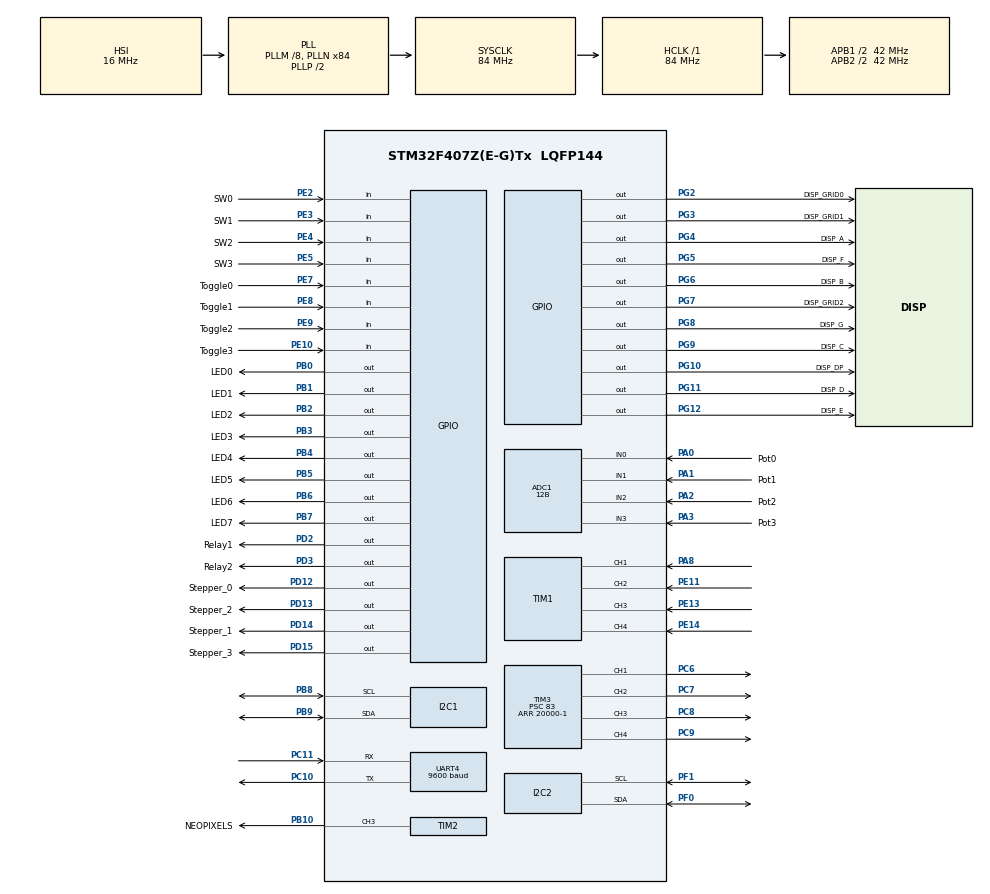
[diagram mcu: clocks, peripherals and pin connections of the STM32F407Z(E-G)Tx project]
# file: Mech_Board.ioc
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ADC1.Channel-0\#ChannelRegularConversion=ADC_CHANNEL_0
ADC1.Channel-1\#ChannelRegularConversion=ADC_CHANNEL_1
ADC1.Channel-2\#ChannelRegularConversion=ADC_CHANNEL_2
ADC1.Channel-3\#ChannelRegularConversion=ADC_CHANNEL_3
ADC1.ClockPrescaler=ADC_CLOCK_SYNC_PCLK_DIV8
ADC1.ContinuousConvMode=ENABLE
ADC1.DMAContinuousRequests=ENABLE
ADC1.NbrOfConversion=4
ADC1.NbrOfConversionFlag=1
ADC1.Rank-0\#ChannelRegularConversion=1
ADC1.Rank-1\#ChannelRegularConversion=2
ADC1.Rank-2\#ChannelRegularConversion=3
ADC1.Rank-3\#ChannelRegularConversion=4
ADC1.Resolution=ADC_RESOLUTION_12B
ADC1.SamplingTime-0\#ChannelRegularConversion=ADC_SAMPLETIME_3CYCLES
ADC1.SamplingTime-1\#ChannelRegularConversion=ADC_SAMPLETIME_3CYCLES
ADC1.SamplingTime-2\#ChannelRegularConversion=ADC_SAMPLETIME_3CYCLES
ADC1.SamplingTime-3\#ChannelRegularConversion=ADC_SAMPLETIME_3CYCLES
ADC1.ScanConvMode=ENABLE
ADC1.master=1
Dma.ADC1.1.Direction=DMA_PERIPH_TO_MEMORY
Dma.ADC1.1.FIFOMode=DMA_FIFOMODE_DISABLE
Dma.ADC1.1.Instance=DMA2_Stream0
Dma.ADC1.1.MemDataAlignment=DMA_MDATAALIGN_HALFWORD
Dma.ADC1.1.MemInc=DMA_MINC_ENABLE
Dma.ADC1.1.Mode=DMA_CIRCULAR
Dma.ADC1.1.PeriphDataAlignment=DMA_PDATAALIGN_HALFWORD
Dma.ADC1.1.PeriphInc=DMA_PINC_DISABLE
Dma.ADC1.1.Priority=DMA_PRIORITY_LOW
Dma.Request0=TIM2_UP/CH3
Dma.Request1=ADC1
Dma.Request2=TIM3_CH3
Dma.Request3=TIM3_CH4/UP
Dma.TIM2_UP/CH3.0.Direction=DMA_MEMORY_TO_PERIPH
Dma.TIM2_UP/CH3.0.FIFOMode=DMA_FIFOMODE_DISABLE
Dma.TIM2_UP/CH3.0.Instance=DMA1_Stream1
Dma.TIM2_UP/CH3.0.MemDataAlignment=DMA_MDATAALIGN_WORD
Dma.TIM2_UP/CH3.0.MemInc=DMA_MINC_ENABLE
Dma.TIM2_UP/CH3.0.Mode=DMA_NORMAL
Dma.TIM2_UP/CH3.0.PeriphDataAlignment=DMA_PDATAALIGN_WORD
Dma.TIM2_UP/CH3.0.PeriphInc=DMA_PINC_DISABLE
Dma.TIM2_UP/CH3.0.Priority=DMA_PRIORITY_LOW
Dma.TIM3_CH3.2.Direction=DMA_MEMORY_TO_PERIPH
Dma.TIM3_CH3.2.FIFOMode=DMA_FIFOMODE_DISABLE
Dma.TIM3_CH3.2.Instance=DMA1_Stream7
Dma.TIM3_CH3.2.MemDataAlignment=DMA_MDATAALIGN_HALFWORD
Dma.TIM3_CH3.2.MemInc=DMA_MINC_ENABLE
Dma.TIM3_CH3.2.Mode=DMA_NORMAL
Dma.TIM3_CH3.2.PeriphDataAlignment=DMA_PDATAALIGN_HALFWORD
Dma.TIM3_CH3.2.PeriphInc=DMA_PINC_DISABLE
Dma.TIM3_CH3.2.Priority=DMA_PRIORITY_LOW
Dma.TIM3_CH4/UP.3.Direction=DMA_MEMORY_TO_PERIPH
Dma.TIM3_CH4/UP.3.FIFOMode=DMA_FIFOMODE_DISABLE
Dma.TIM3_CH4/UP.3.Instance=DMA1_Stream2
Dma.TIM3_CH4/UP.3.MemDataAlignment=DMA_MDATAALIGN_HALFWORD
Dma.TIM3_CH4/UP.3.MemInc=DMA_MINC_ENABLE
Dma.TIM3_CH4/UP.3.Mode=DMA_NORMAL
Dma.TIM3_CH4/UP.3.PeriphDataAlignment=DMA_PDATAALIGN_HALFWORD
Dma.TIM3_CH4/UP.3.PeriphInc=DMA_PINC_DISABLE
Dma.TIM3_CH4/UP.3.Priority=DMA_PRIORITY_LOW
Mcu.Family=STM32F4
Mcu.Name=STM32F407Z(E-G)Tx
Mcu.Package=LQFP144
NVIC.DMA1_Stream1_IRQn=true\:0\:0\:true\:false\:true\:false\:true\:true
NVIC.DMA1_Stream2_IRQn=true\:0\:0\:false\:false\:true\:false\:true\:true
NVIC.DMA1_Stream7_IRQn=true\:0\:0\:false\:false\:true\:false\:true\:true
NVIC.DMA2_Stream0_IRQn=true\:0\:0\:false\:false\:true\:false\:true\:true
NVIC.PriorityGroup=NVIC_PRIORITYGROUP_4
NVIC.TIM1_CC_IRQn=true\:0\:0\:false\:false\:true\:true\:true\:true
NVIC.TIM2_IRQn=true\:0\:0\:false\:false\:true\:true\:true\:true
NVIC.TIM4_IRQn=true\:0\:0\:true\:false\:true\:true\:true\:true
NVIC.TIM5_IRQn=true\:0\:0\:false\:false\:true\:true\:true\:true
NVIC.TIM6_DAC_IRQn=true\:0\:0\:false\:false\:true\:true\:true\:true
NVIC.TIM7_IRQn=true\:0\:0\:true\:false\:true\:true\:true\:true
NVIC.UART4_IRQn=true\:0\:0\:false\:false\:true\:true\:true\:true
PA0-WKUP.GPIO_Label=Pot0
PA0-WKUP.Signal=ADCx_IN0
PA1.GPIO_Label=Pot1
PA1.Signal=ADCx_IN1
PA2.GPIO_Label=Pot2
PA2.Signal=ADCx_IN2
PA3.GPIO_Label=Pot3
PA3.Signal=ADCx_IN3
PA8.Signal=S_TIM1_CH1
PB0.GPIO_Label=LED0
PB0.Signal=GPIO_Output
PB1.GPIO_Label=LED1
PB1.Signal=GPIO_Output
PB10.GPIO_Label=NEOPIXELS
PB10.GPIO_ModeDefaultPP=GPIO_MODE_AF_PP
PB10.GPIO_PuPd=GPIO_NOPULL
PB10.GPIO_Speed=GPIO_SPEED_FREQ_VERY_HIGH
PB10.Signal=S_TIM2_CH3
PB2.GPIO_Label=LED2
PB2.Signal=GPIO_Output
PB3.GPIO_Label=LED3
PB3.Signal=GPIO_Output
PB4.GPIO_Label=LED4
PB4.Signal=GPIO_Output
PB5.GPIO_Label=LED5
PB5.Signal=GPIO_Output
PB6.GPIO_Label=LED6
PB6.Signal=GPIO_Output
PB7.GPIO_Label=LED7
PB7.Signal=GPIO_Output
PB8.Mode=I2C
PB8.Signal=I2C1_SCL
PB9.Mode=I2C
PB9.Signal=I2C1_SDA
PC10.Mode=Asynchronous
PC10.Signal=UART4_TX
PC11.Mode=Asynchronous
PC11.Signal=UART4_RX
PC6.Signal=S_TIM3_CH1
PC7.Signal=S_TIM3_CH2
PC8.Signal=S_TIM3_CH3
PC9.Signal=S_TIM3_CH4
PD12.GPIO_Label=Stepper_0
PD12.GPIO_Speed=GPIO_SPEED_FREQ_VERY_HIGH
PD12.Signal=GPIO_Output
PD13.GPIO_Label=Stepper_2
PD13.GPIO_Speed=GPIO_SPEED_FREQ_VERY_HIGH
PD13.Signal=GPIO_Output
PD14.GPIO_Label=Stepper_1
PD14.GPIO_Speed=GPIO_SPEED_FREQ_VERY_HIGH
PD14.Signal=GPIO_Output
PD15.GPIO_Label=Stepper_3
PD15.GPIO_Speed=GPIO_SPEED_FREQ_VERY_HIGH
PD15.Signal=GPIO_Output
PD2.GPIO_Label=Relay1
PD2.GPIO_Speed=GPIO_SPEED_FREQ_VERY_HIGH
PD2.Signal=GPIO_Output
PD3.GPIO_Label=Relay2
PD3.GPIO_Speed=GPIO_SPEED_FREQ_VERY_HIGH
PD3.Signal=GPIO_Output
PE10.GPIO_Label=Toggle3
PE10.Signal=GPIO_Input
PE11.Signal=S_TIM1_CH2
PE13.Signal=S_TIM1_CH3
PE14.Signal=S_TIM1_CH4
PE2.GPIO_Label=SW0
PE2.Signal=GPIO_Input
PE3.GPIO_Label=SW1
PE3.Signal=GPIO_Input
PE4.GPIO_Label=SW2
PE4.Signal=GPIO_Input
PE5.GPIO_Label=SW3
PE5.Signal=GPIO_Input
PE7.GPIO_Label=Toggle0
PE7.Signal=GPIO_Input
PE8.GPIO_Label=Toggle1
PE8.Signal=GPIO_Input
PE9.GPIO_Label=Toggle2
PE9.Signal=GPIO_Input
PF0.Mode=I2C
PF0.Signal=I2C2_SDA
PF1.Mode=I2C
PF1.Signal=I2C2_SCL
PG10.GPIO_Label=DISP_DP
PG10.Signal=GPIO_Output
PG11.GPIO_Label=DISP_D
PG11.GPIO_Speed=GPIO_SPEED_FREQ_VERY_HIGH
PG11.Signal=GPIO_Output
PG12.GPIO_Label=DISP_E
PG12.GPIO_Speed=GPIO_SPEED_FREQ_VERY_HIGH
PG12.PinState=GPIO_PIN_RESET
PG12.Signal=GPIO_Output
PG2.GPIO_Label=DISP_GRID0
PG2.PinState=GPIO_PIN_RESET
PG2.Signal=GPIO_Output
PG3.GPIO_Label=DISP_GRID1
PG3.Signal=GPIO_Output
PG4.GPIO_Label=DISP_A
PG4.GPIO_Speed=GPIO_SPEED_FREQ_VERY_HIGH
PG4.PinState=GPIO_PIN_RESET
PG4.Signal=GPIO_Output
PG5.GPIO_Label=DISP_F
PG5.GPIO_Speed=GPIO_SPEED_FREQ_VERY_HIGH
PG5.Signal=GPIO_Output
PG6.GPIO_Label=DISP_B
PG6.GPIO_Speed=GPIO_SPEED_FREQ_VERY_HIGH
PG6.Signal=GPIO_Output
PG7.GPIO_Label=DISP_GRID2
PG7.Signal=GPIO_Output
PG8.GPIO_Label=DISP_G
PG8.GPIO_Speed=GPIO_SPEED_FREQ_VERY_HIGH
PG8.Signal=GPIO_Output
PG9.GPIO_Label=DISP_C
PG9.GPIO_Speed=GPIO_SPEED_FREQ_VERY_HIGH
PG9.Signal=GPIO_Output
ProjectManager.HeapSize=0x200
ProjectManager.StackSize=0x400
ProjectManager.TargetToolchain=Makefile
RCC.48MHZClocksFreq_Value=42000000
RCC.AHBFreq_Value=84000000
RCC.APB1CLKDivider=RCC_HCLK_DIV2
RCC.APB1Freq_Value=42000000
RCC.APB1TimFreq_Value=84000000
RCC.APB2CLKDivider=RCC_HCLK_DIV2
RCC.APB2Freq_Value=42000000
RCC.APB2TimFreq_Value=84000000
RCC.CortexFreq_Value=84000000
RCC.HCLKFreq_Value=84000000
RCC.HSE_VALUE=25000000
RCC.HSI_VALUE=16000000
RCC.LSE_VALUE=32768
RCC.PLLM=8
RCC.PLLN=84
RCC.SYSCLKFreq_VALUE=84000000
RCC.SYSCLKSource=RCC_SYSCLKSOURCE_PLLCLK
RCC.VCOOutputFreq_Value=168000000
SH.ADCx_IN0.0=ADC1_IN0,IN0
SH.ADCx_IN1.0=ADC1_IN1,IN1
SH.ADCx_IN2.0=ADC1_IN2,IN2
SH.ADCx_IN3.0=ADC1_IN3,IN3
SH.S_TIM1_CH1.0=TIM1_CH1,Input_Capture1_from_TI1
SH.S_TIM1_CH2.0=TIM1_CH2,Input_Capture2_from_TI2
SH.S_TIM1_CH3.0=TIM1_CH3,Input_Capture3_from_TI3
SH.S_TIM1_CH4.0=TIM1_CH4,Input_Capture4_from_TI4
SH.S_TIM2_CH3.0=TIM2_CH3,PWM Generation3 CH3
SH.S_TIM3_CH1.0=TIM3_CH1,PWM Generation1 CH1
SH.S_TIM3_CH2.0=TIM3_CH2,PWM Generation2 CH2
SH.S_TIM3_CH3.0=TIM3_CH3,PWM Generation3 CH3
SH.S_TIM3_CH4.0=TIM3_CH4,PWM Generation4 CH4
TIM1.Channel-Input_Capture1_from_TI1=TIM_CHANNEL_1
TIM1.Channel-Input_Capture2_from_TI2=TIM_CHANNEL_2
TIM1.Channel-Input_Capture3_from_TI3=TIM_CHANNEL_3
TIM1.Channel-Input_Capture4_from_TI4=TIM_CHANNEL_4
TIM1.ICPolarity_CH1=TIM_INPUTCHANNELPOLARITY_BOTHEDGE
TIM1.ICPolarity_CH2=TIM_INPUTCHANNELPOLARITY_BOTHEDGE
TIM1.ICPolarity_CH3=TIM_INPUTCHANNELPOLARITY_BOTHEDGE
TIM1.ICPolarity_CH4=TIM_INPUTCHANNELPOLARITY_BOTHEDGE
TIM2.AutoReloadPreload=TIM_AUTORELOAD_PRELOAD_DISABLE
TIM2.Channel-PWM\ Generation3\ CH3=TIM_CHANNEL_3
TIM2.OCFastMode_PWM-PWM\ Generation3\ CH3=TIM_OCFAST_DISABLE
TIM2.Period=104
TIM2.Prescaler=0
TIM3.AutoReloadPreload=TIM_AUTORELOAD_PRELOAD_ENABLE
TIM3.Channel-PWM\ Generation1\ CH1=TIM_CHANNEL_1
TIM3.Channel-PWM\ Generation2\ CH2=TIM_CHANNEL_2
TIM3.Channel-PWM\ Generation3\ CH3=TIM_CHANNEL_3
TIM3.Channel-PWM\ Generation4\ CH4=TIM_CHANNEL_4
TIM3.Period=20000-1
TIM3.Prescaler=83
TIM4.AutoReloadPreload=TIM_AUTORELOAD_PRELOAD_ENABLE
TIM4.ClockDivision=TIM_CLOCKDIVISION_DIV1
TIM4.Period=8400
TIM4.Prescaler=9999
TIM5.Period=10000-1
TIM5.Prescaler=(8400/3/60)-1
TIM6.Period=10000-1
TIM6.Prescaler=8400-1
TIM7.Period=10000-1
TIM7.Prescaler=(8400/3/60)-1
UART4.BaudRate=9600
UART4.VirtualMode=Asynchronous
VP_TIM1_VS_ClockSourceINT.Mode=Internal
VP_TIM2_VS_ClockSourceINT.Mode=Internal
VP_TIM3_VS_ClockSourceINT.Mode=Internal
VP_TIM4_VS_ClockSourceINT.Mode=Internal
VP_TIM5_VS_ClockSourceINT.Mode=Internal
VP_TIM6_VS_ClockSourceINT.Mode=Enable_Timer
VP_TIM7_VS_ClockSourceINT.Mode=Enable_Timer
board=custom

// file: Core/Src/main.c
/* USER CODE BEGIN Header */
/**
  ******************************************************************************
  * @file           : main.c
  * @brief          : Main program body
  * @authors        : Jesse Jabez Arendse
  ******************************************************************************
  * @attention
  *
  * Copyright (c) 2023 STMicroelectronics.
  * All rights reserved.
  *
  * This software is licensed under terms that can be found in the LICENSE file
  * in the root directory of this software component.
  * If no LICENSE file comes with this software, it is provided AS-IS.
  *
  ******************************************************************************
  */
/* USER CODE END Header */
#include "main.h"

/* USER CODE BEGIN Includes */
#include <math.h>

#include "7SegDisplay.h"
#include "CurrentMonitor.h"
#include "Pots.h"
#include "IMU.h"
#include "StepperMotor.h"
#include "ServoMotors.h"
#include "Relays.h"
#include "NeoPixels.h"
#include "USB.h"

/* USER CODE END Includes */

/* USER CODE BEGIN PD */
#define MPU_ADDRESS		0b1101001<<1

/* USER CODE END PD */

ADC_HandleTypeDef hadc1;
DMA_HandleTypeDef hdma_adc1;

I2C_HandleTypeDef hi2c1;
I2C_HandleTypeDef hi2c2;

TIM_HandleTypeDef htim1;
TIM_HandleTypeDef htim2;
TIM_HandleTypeDef htim3;
TIM_HandleTypeDef htim4;
TIM_HandleTypeDef htim5;
TIM_HandleTypeDef htim6;
TIM_HandleTypeDef htim7;
DMA_HandleTypeDef hdma_tim2_up_ch3;
DMA_HandleTypeDef hdma_tim3_ch3;
DMA_HandleTypeDef hdma_tim3_ch4_up;

UART_HandleTypeDef huart4;

/* USER CODE BEGIN PV */

uint16_t POTS[ADC_CHANNEL_NUM];

/* USER CODE END PV */

void SystemClock_Config(void);
static void MX_GPIO_Init(void);
static void MX_DMA_Init(void);
static void MX_TIM2_Init(void);
static void MX_UART4_Init(void);
static void MX_I2C1_Init(void);
static void MX_ADC1_Init(void);
static void MX_TIM7_Init(void);
static void MX_TIM6_Init(void);
static void MX_I2C2_Init(void);
static void MX_TIM4_Init(void);
static void MX_TIM1_Init(void);
static void MX_TIM3_Init(void);
static void MX_TIM5_Init(void);

int main(void)
{

  /* MCU Configuration--------------------------------------------------------*/

  /* Reset of all peripherals, Initializes the Flash interface and the Systick. */
  HAL_Init();

  /* Configure the system clock */
  SystemClock_Config();

  /* Initialize all configured peripherals */
  MX_GPIO_Init();
  MX_DMA_Init();
  MX_TIM2_Init();
  MX_UART4_Init();
  MX_I2C1_Init();
  MX_ADC1_Init();
  MX_TIM7_Init();
  MX_TIM6_Init();
  MX_I2C2_Init();
  MX_TIM4_Init();
  MX_TIM1_Init();
  MX_TIM3_Init();
  MX_TIM5_Init();

  /* Infinite loop */
  while (1)
  {
  }

}

void SystemClock_Config(void)
{
  RCC_OscInitTypeDef RCC_OscInitStruct = {0};
  RCC_ClkInitTypeDef RCC_ClkInitStruct = {0};

  /** Configure the main internal regulator output voltage
  */
  __HAL_RCC_PWR_CLK_ENABLE();
  __HAL_PWR_VOLTAGESCALING_CONFIG(PWR_REGULATOR_VOLTAGE_SCALE1);

  /** Initializes the RCC Oscillators according to the specified parameters
  * in the RCC_OscInitTypeDef structure.
  */
  RCC_OscInitStruct.OscillatorType = RCC_OSCILLATORTYPE_HSI;
  RCC_OscInitStruct.HSIState = RCC_HSI_ON;
  RCC_OscInitStruct.HSICalibrationValue = RCC_HSICALIBRATION_DEFAULT;
  RCC_OscInitStruct.PLL.PLLState = RCC_PLL_ON;
  RCC_OscInitStruct.PLL.PLLSource = RCC_PLLSOURCE_HSI;
  RCC_OscInitStruct.PLL.PLLM = 8;
  RCC_OscInitStruct.PLL.PLLN = 84;
  RCC_OscInitStruct.PLL.PLLP = RCC_PLLP_DIV2;
  RCC_OscInitStruct.PLL.PLLQ = 4;
  if (HAL_RCC_OscConfig(&RCC_OscInitStruct) != HAL_OK)
  {
    Error_Handler();
  }

  /** Initializes the CPU, AHB and APB buses clocks
  */
  RCC_ClkInitStruct.ClockType = RCC_CLOCKTYPE_HCLK|RCC_CLOCKTYPE_SYSCLK
                              |RCC_CLOCKTYPE_PCLK1|RCC_CLOCKTYPE_PCLK2;
  RCC_ClkInitStruct.SYSCLKSource = RCC_SYSCLKSOURCE_PLLCLK;
  RCC_ClkInitStruct.AHBCLKDivider = RCC_SYSCLK_DIV1;
  RCC_ClkInitStruct.APB1CLKDivider = RCC_HCLK_DIV2;
  RCC_ClkInitStruct.APB2CLKDivider = RCC_HCLK_DIV2;

  if (HAL_RCC_ClockConfig(&RCC_ClkInitStruct, FLASH_LATENCY_2) != HAL_OK)
  {
    Error_Handler();
  }
}

static void MX_ADC1_Init(void)
{

  ADC_ChannelConfTypeDef sConfig = {0};

  /** Configure the global features of the ADC (Clock, Resolution, Data Alignment and number of conversion)
  */
  hadc1.Instance = ADC1;
  hadc1.Init.ClockPrescaler = ADC_CLOCK_SYNC_PCLK_DIV8;
  hadc1.Init.Resolution = ADC_RESOLUTION_12B;
  hadc1.Init.ScanConvMode = ENABLE;
  hadc1.Init.ContinuousConvMode = ENABLE;
  hadc1.Init.DiscontinuousConvMode = DISABLE;
  hadc1.Init.ExternalTrigConvEdge = ADC_EXTERNALTRIGCONVEDGE_NONE;
  hadc1.Init.ExternalTrigConv = ADC_SOFTWARE_START;
  hadc1.Init.DataAlign = ADC_DATAALIGN_RIGHT;
  hadc1.Init.NbrOfConversion = 4;
  hadc1.Init.DMAContinuousRequests = ENABLE;
  hadc1.Init.EOCSelection = ADC_EOC_SINGLE_CONV;
  if (HAL_ADC_Init(&hadc1) != HAL_OK)
  {
    Error_Handler();
  }

  /** Configure for the selected ADC regular channel its corresponding rank in the sequencer and its sample time.
  */
  sConfig.Channel = ADC_CHANNEL_0;
  sConfig.Rank = 1;
  sConfig.SamplingTime = ADC_SAMPLETIME_3CYCLES;
  if (HAL_ADC_ConfigChannel(&hadc1, &sConfig) != HAL_OK)
  {
    Error_Handler();
  }

  /** Configure for the selected ADC regular channel its corresponding rank in the sequencer and its sample time.
  */
  sConfig.Channel = ADC_CHANNEL_1;
  sConfig.Rank = 2;
  if (HAL_ADC_ConfigChannel(&hadc1, &sConfig) != HAL_OK)
  {
    Error_Handler();
  }

  /** Configure for the selected ADC regular channel its corresponding rank in the sequencer and its sample time.
  */
  sConfig.Channel = ADC_CHANNEL_2;
  sConfig.Rank = 3;
  if (HAL_ADC_ConfigChannel(&hadc1, &sConfig) != HAL_OK)
  {
    Error_Handler();
  }

  /** Configure for the selected ADC regular channel its corresponding rank in the sequencer and its sample time.
  */
  sConfig.Channel = ADC_CHANNEL_3;
  sConfig.Rank = 4;
  if (HAL_ADC_ConfigChannel(&hadc1, &sConfig) != HAL_OK)
  {
    Error_Handler();
  }

}

static void MX_I2C1_Init(void)
{

  hi2c1.Instance = I2C1;
  hi2c1.Init.ClockSpeed = 100000;
  hi2c1.Init.DutyCycle = I2C_DUTYCYCLE_2;
  hi2c1.Init.OwnAddress1 = 0;
  hi2c1.Init.AddressingMode = I2C_ADDRESSINGMODE_7BIT;
  hi2c1.Init.DualAddressMode = I2C_DUALADDRESS_DISABLE;
  hi2c1.Init.OwnAddress2 = 0;
  hi2c1.Init.GeneralCallMode = I2C_GENERALCALL_DISABLE;
  hi2c1.Init.NoStretchMode = I2C_NOSTRETCH_DISABLE;
  if (HAL_I2C_Init(&hi2c1) != HAL_OK)
  {
    Error_Handler();
  }

}

static void MX_I2C2_Init(void)
{

  hi2c2.Instance = I2C2;
  hi2c2.Init.ClockSpeed = 100000;
  hi2c2.Init.DutyCycle = I2C_DUTYCYCLE_2;
  hi2c2.Init.OwnAddress1 = 0;
  hi2c2.Init.AddressingMode = I2C_ADDRESSINGMODE_7BIT;
  hi2c2.Init.DualAddressMode = I2C_DUALADDRESS_DISABLE;
  hi2c2.Init.OwnAddress2 = 0;
  hi2c2.Init.GeneralCallMode = I2C_GENERALCALL_DISABLE;
  hi2c2.Init.NoStretchMode = I2C_NOSTRETCH_DISABLE;
  if (HAL_I2C_Init(&hi2c2) != HAL_OK)
  {
    Error_Handler();
  }

}

static void MX_TIM1_Init(void)
{

  TIM_ClockConfigTypeDef sClockSourceConfig = {0};
  TIM_MasterConfigTypeDef sMasterConfig = {0};
  TIM_IC_InitTypeDef sConfigIC = {0};

  htim1.Instance = TIM1;
  htim1.Init.Prescaler = 0;
  htim1.Init.CounterMode = TIM_COUNTERMODE_UP;
  htim1.Init.Period = 65535;
  htim1.Init.ClockDivision = TIM_CLOCKDIVISION_DIV1;
  htim1.Init.RepetitionCounter = 0;
  htim1.Init.AutoReloadPreload = TIM_AUTORELOAD_PRELOAD_DISABLE;
  if (HAL_TIM_Base_Init(&htim1) != HAL_OK)
  {
    Error_Handler();
  }
  sClockSourceConfig.ClockSource = TIM_CLOCKSOURCE_INTERNAL;
  if (HAL_TIM_ConfigClockSource(&htim1, &sClockSourceConfig) != HAL_OK)
  {
    Error_Handler();
  }
  if (HAL_TIM_IC_Init(&htim1) != HAL_OK)
  {
    Error_Handler();
  }
  sMasterConfig.MasterOutputTrigger = TIM_TRGO_RESET;
  sMasterConfig.MasterSlaveMode = TIM_MASTERSLAVEMODE_DISABLE;
  if (HAL_TIMEx_MasterConfigSynchronization(&htim1, &sMasterConfig) != HAL_OK)
  {
    Error_Handler();
  }
  sConfigIC.ICPolarity = TIM_INPUTCHANNELPOLARITY_BOTHEDGE;
  sConfigIC.ICSelection = TIM_ICSELECTION_DIRECTTI;
  sConfigIC.ICPrescaler = TIM_ICPSC_DIV1;
  sConfigIC.ICFilter = 0;
  if (HAL_TIM_IC_ConfigChannel(&htim1, &sConfigIC, TIM_CHANNEL_1) != HAL_OK)
  {
    Error_Handler();
  }
  if (HAL_TIM_IC_ConfigChannel(&htim1, &sConfigIC, TIM_CHANNEL_2) != HAL_OK)
  {
    Error_Handler();
  }
  if (HAL_TIM_IC_ConfigChannel(&htim1, &sConfigIC, TIM_CHANNEL_3) != HAL_OK)
  {
    Error_Handler();
  }
  if (HAL_TIM_IC_ConfigChannel(&htim1, &sConfigIC, TIM_CHANNEL_4) != HAL_OK)
  {
    Error_Handler();
  }

}

static void MX_TIM2_Init(void)
{

  TIM_ClockConfigTypeDef sClockSourceConfig = {0};
  TIM_MasterConfigTypeDef sMasterConfig = {0};
  TIM_OC_InitTypeDef sConfigOC = {0};

  htim2.Instance = TIM2;
  htim2.Init.Prescaler = 0;
  htim2.Init.CounterMode = TIM_COUNTERMODE_UP;
  htim2.Init.Period = 104;
  htim2.Init.ClockDivision = TIM_CLOCKDIVISION_DIV1;
  htim2.Init.AutoReloadPreload = TIM_AUTORELOAD_PRELOAD_DISABLE;
  if (HAL_TIM_Base_Init(&htim2) != HAL_OK)
  {
    Error_Handler();
  }
  sClockSourceConfig.ClockSource = TIM_CLOCKSOURCE_INTERNAL;
  if (HAL_TIM_ConfigClockSource(&htim2, &sClockSourceConfig) != HAL_OK)
  {
    Error_Handler();
  }
  if (HAL_TIM_PWM_Init(&htim2) != HAL_OK)
  {
    Error_Handler();
  }
  sMasterConfig.MasterOutputTrigger = TIM_TRGO_RESET;
  sMasterConfig.MasterSlaveMode = TIM_MASTERSLAVEMODE_DISABLE;
  if (HAL_TIMEx_MasterConfigSynchronization(&htim2, &sMasterConfig) != HAL_OK)
  {
    Error_Handler();
  }
  sConfigOC.OCMode = TIM_OCMODE_PWM1;
  sConfigOC.Pulse = 0;
  sConfigOC.OCPolarity = TIM_OCPOLARITY_HIGH;
  sConfigOC.OCFastMode = TIM_OCFAST_DISABLE;
  if (HAL_TIM_PWM_ConfigChannel(&htim2, &sConfigOC, TIM_CHANNEL_3) != HAL_OK)
  {
    Error_Handler();
  }
  HAL_TIM_MspPostInit(&htim2);

}

static void MX_TIM3_Init(void)
{

  TIM_ClockConfigTypeDef sClockSourceConfig = {0};
  TIM_MasterConfigTypeDef sMasterConfig = {0};
  TIM_OC_InitTypeDef sConfigOC = {0};

  htim3.Instance = TIM3;
  htim3.Init.Prescaler = 83;
  htim3.Init.CounterMode = TIM_COUNTERMODE_UP;
  htim3.Init.Period = 20000-1;
  htim3.Init.ClockDivision = TIM_CLOCKDIVISION_DIV1;
  htim3.Init.AutoReloadPreload = TIM_AUTORELOAD_PRELOAD_ENABLE;
  if (HAL_TIM_Base_Init(&htim3) != HAL_OK)
  {
    Error_Handler();
  }
  sClockSourceConfig.ClockSource = TIM_CLOCKSOURCE_INTERNAL;
  if (HAL_TIM_ConfigClockSource(&htim3, &sClockSourceConfig) != HAL_OK)
  {
    Error_Handler();
  }
  if (HAL_TIM_PWM_Init(&htim3) != HAL_OK)
  {
    Error_Handler();
  }
  sMasterConfig.MasterOutputTrigger = TIM_TRGO_RESET;
  sMasterConfig.MasterSlaveMode = TIM_MASTERSLAVEMODE_DISABLE;
  if (HAL_TIMEx_MasterConfigSynchronization(&htim3, &sMasterConfig) != HAL_OK)
  {
    Error_Handler();
  }
  sConfigOC.OCMode = TIM_OCMODE_PWM1;
  sConfigOC.Pulse = 0;
  sConfigOC.OCPolarity = TIM_OCPOLARITY_HIGH;
  sConfigOC.OCFastMode = TIM_OCFAST_DISABLE;
  if (HAL_TIM_PWM_ConfigChannel(&htim3, &sConfigOC, TIM_CHANNEL_1) != HAL_OK)
  {
    Error_Handler();
  }
  if (HAL_TIM_PWM_ConfigChannel(&htim3, &sConfigOC, TIM_CHANNEL_2) != HAL_OK)
  {
    Error_Handler();
  }
  if (HAL_TIM_PWM_ConfigChannel(&htim3, &sConfigOC, TIM_CHANNEL_3) != HAL_OK)
  {
    Error_Handler();
  }
  if (HAL_TIM_PWM_ConfigChannel(&htim3, &sConfigOC, TIM_CHANNEL_4) != HAL_OK)
  {
    Error_Handler();
  }
  HAL_TIM_MspPostInit(&htim3);

}

static void MX_TIM4_Init(void)
{

  TIM_ClockConfigTypeDef sClockSourceConfig = {0};
  TIM_MasterConfigTypeDef sMasterConfig = {0};

  htim4.Instance = TIM4;
  htim4.Init.Prescaler = 9999;
  htim4.Init.CounterMode = TIM_COUNTERMODE_UP;
  htim4.Init.Period = 8400;
  htim4.Init.ClockDivision = TIM_CLOCKDIVISION_DIV1;
  htim4.Init.AutoReloadPreload = TIM_AUTORELOAD_PRELOAD_ENABLE;
  if (HAL_TIM_Base_Init(&htim4) != HAL_OK)
  {
    Error_Handler();
  }
  sClockSourceConfig.ClockSource = TIM_CLOCKSOURCE_INTERNAL;
  if (HAL_TIM_ConfigClockSource(&htim4, &sClockSourceConfig) != HAL_OK)
  {
    Error_Handler();
  }
  sMasterConfig.MasterOutputTrigger = TIM_TRGO_RESET;
  sMasterConfig.MasterSlaveMode = TIM_MASTERSLAVEMODE_DISABLE;
  if (HAL_TIMEx_MasterConfigSynchronization(&htim4, &sMasterConfig) != HAL_OK)
  {
    Error_Handler();
  }

}

static void MX_TIM5_Init(void)
{

  TIM_ClockConfigTypeDef sClockSourceConfig = {0};
  TIM_MasterConfigTypeDef sMasterConfig = {0};

  htim5.Instance = TIM5;
  htim5.Init.Prescaler = (8400/3/60)-1;
  htim5.Init.CounterMode = TIM_COUNTERMODE_UP;
  htim5.Init.Period = 10000-1;
  htim5.Init.ClockDivision = TIM_CLOCKDIVISION_DIV1;
  htim5.Init.AutoReloadPreload = TIM_AUTORELOAD_PRELOAD_DISABLE;
  if (HAL_TIM_Base_Init(&htim5) != HAL_OK)
  {
    Error_Handler();
  }
  sClockSourceConfig.ClockSource = TIM_CLOCKSOURCE_INTERNAL;
  if (HAL_TIM_ConfigClockSource(&htim5, &sClockSourceConfig) != HAL_OK)
  {
    Error_Handler();
  }
  sMasterConfig.MasterOutputTrigger = TIM_TRGO_RESET;
  sMasterConfig.MasterSlaveMode = TIM_MASTERSLAVEMODE_DISABLE;
  if (HAL_TIMEx_MasterConfigSynchronization(&htim5, &sMasterConfig) != HAL_OK)
  {
    Error_Handler();
  }

}

static void MX_TIM6_Init(void)
{

  TIM_MasterConfigTypeDef sMasterConfig = {0};

  htim6.Instance = TIM6;
  htim6.Init.Prescaler = 8400-1;
  htim6.Init.CounterMode = TIM_COUNTERMODE_UP;
  htim6.Init.Period = 10000-1;
  htim6.Init.AutoReloadPreload = TIM_AUTORELOAD_PRELOAD_DISABLE;
  if (HAL_TIM_Base_Init(&htim6) != HAL_OK)
  {
    Error_Handler();
  }
  sMasterConfig.MasterOutputTrigger = TIM_TRGO_RESET;
  sMasterConfig.MasterSlaveMode = TIM_MASTERSLAVEMODE_DISABLE;
  if (HAL_TIMEx_MasterConfigSynchronization(&htim6, &sMasterConfig) != HAL_OK)
  {
    Error_Handler();
  }

}

static void MX_TIM7_Init(void)
{

  TIM_MasterConfigTypeDef sMasterConfig = {0};

  /* USER CODE BEGIN TIM7_Init 1 */

  // prescalar and ARR setup to theoretically achieve 240Hz display refresh rate
  /* USER CODE END TIM7_Init 1 */
  htim7.Instance = TIM7;
  htim7.Init.Prescaler = (8400/3/60)-1;
  htim7.Init.CounterMode = TIM_COUNTERMODE_UP;
  htim7.Init.Period = 10000-1;
  htim7.Init.AutoReloadPreload = TIM_AUTORELOAD_PRELOAD_DISABLE;
  if (HAL_TIM_Base_Init(&htim7) != HAL_OK)
  {
    Error_Handler();
  }
  sMasterConfig.MasterOutputTrigger = TIM_TRGO_RESET;
  sMasterConfig.MasterSlaveMode = TIM_MASTERSLAVEMODE_DISABLE;
  if (HAL_TIMEx_MasterConfigSynchronization(&htim7, &sMasterConfig) != HAL_OK)
  {
    Error_Handler();
  }

}

static void MX_UART4_Init(void)
{

  huart4.Instance = UART4;
  huart4.Init.BaudRate = 9600;
  huart4.Init.WordLength = UART_WORDLENGTH_8B;
  huart4.Init.StopBits = UART_STOPBITS_1;
  huart4.Init.Parity = UART_PARITY_NONE;
  huart4.Init.Mode = UART_MODE_TX_RX;
  huart4.Init.HwFlowCtl = UART_HWCONTROL_NONE;
  huart4.Init.OverSampling = UART_OVERSAMPLING_16;
  if (HAL_UART_Init(&huart4) != HAL_OK)
  {
    Error_Handler();
  }

}

static void MX_DMA_Init(void)
{

  /* DMA controller clock enable */
  __HAL_RCC_DMA1_CLK_ENABLE();
  __HAL_RCC_DMA2_CLK_ENABLE();

  /* DMA interrupt init */
  /* DMA1_Stream1_IRQn interrupt configuration */
  HAL_NVIC_SetPriority(DMA1_Stream1_IRQn, 0, 0);
  HAL_NVIC_EnableIRQ(DMA1_Stream1_IRQn);
  /* DMA1_Stream2_IRQn interrupt configuration */
  HAL_NVIC_SetPriority(DMA1_Stream2_IRQn, 0, 0);
  HAL_NVIC_EnableIRQ(DMA1_Stream2_IRQn);
  /* DMA1_Stream7_IRQn interrupt configuration */
  HAL_NVIC_SetPriority(DMA1_Stream7_IRQn, 0, 0);
  HAL_NVIC_EnableIRQ(DMA1_Stream7_IRQn);
  /* DMA2_Stream0_IRQn interrupt configuration */
  HAL_NVIC_SetPriority(DMA2_Stream0_IRQn, 0, 0);
  HAL_NVIC_EnableIRQ(DMA2_Stream0_IRQn);

}

static void MX_GPIO_Init(void)
{
  GPIO_InitTypeDef GPIO_InitStruct = {0};

  /* GPIO Ports Clock Enable */
  __HAL_RCC_GPIOE_CLK_ENABLE();
  __HAL_RCC_GPIOF_CLK_ENABLE();
  __HAL_RCC_GPIOA_CLK_ENABLE();
  __HAL_RCC_GPIOB_CLK_ENABLE();
  __HAL_RCC_GPIOD_CLK_ENABLE();
  __HAL_RCC_GPIOG_CLK_ENABLE();
  __HAL_RCC_GPIOC_CLK_ENABLE();

  /*Configure GPIO pin Output Level */
  HAL_GPIO_WritePin(GPIOB, LED0_Pin|LED1_Pin|LED2_Pin|LED3_Pin
                          |LED4_Pin|LED5_Pin|LED6_Pin|LED7_Pin, GPIO_PIN_RESET);

  /*Configure GPIO pin Output Level */
  HAL_GPIO_WritePin(GPIOD, Stepper_0_Pin|Stepper_2_Pin|Stepper_1_Pin|Stepper_3_Pin
                          |Relay1_Pin|Relay2_Pin, GPIO_PIN_RESET);

  /*Configure GPIO pin Output Level */
  HAL_GPIO_WritePin(GPIOG, DISP_GRID0_Pin|DISP_GRID1_Pin|DISP_A_Pin|DISP_F_Pin
                          |DISP_B_Pin|DISP_GRID2_Pin|DISP_G_Pin|DISP_C_Pin
                          |DISP_DP_Pin|DISP_D_Pin|DISP_E_Pin, GPIO_PIN_RESET);

  /*Configure GPIO pins : SW0_Pin SW1_Pin SW2_Pin SW3_Pin
                           Toggle0_Pin Toggle1_Pin Toggle2_Pin Toggle3_Pin */
  GPIO_InitStruct.Pin = SW0_Pin|SW1_Pin|SW2_Pin|SW3_Pin
                          |Toggle0_Pin|Toggle1_Pin|Toggle2_Pin|Toggle3_Pin;
  GPIO_InitStruct.Mode = GPIO_MODE_INPUT;
  GPIO_InitStruct.Pull = GPIO_NOPULL;
  HAL_GPIO_Init(GPIOE, &GPIO_InitStruct);

  /*Configure GPIO pins : LED0_Pin LED1_Pin LED2_Pin LED3_Pin
                           LED4_Pin LED5_Pin LED6_Pin LED7_Pin */
  GPIO_InitStruct.Pin = LED0_Pin|LED1_Pin|LED2_Pin|LED3_Pin
                          |LED4_Pin|LED5_Pin|LED6_Pin|LED7_Pin;
  GPIO_InitStruct.Mode = GPIO_MODE_OUTPUT_PP;
  GPIO_InitStruct.Pull = GPIO_NOPULL;
  GPIO_InitStruct.Speed = GPIO_SPEED_FREQ_LOW;
  HAL_GPIO_Init(GPIOB, &GPIO_InitStruct);

  /*Configure GPIO pins : Stepper_0_Pin Stepper_2_Pin Stepper_1_Pin Stepper_3_Pin
                           Relay1_Pin Relay2_Pin */
  GPIO_InitStruct.Pin = Stepper_0_Pin|Stepper_2_Pin|Stepper_1_Pin|Stepper_3_Pin
                          |Relay1_Pin|Relay2_Pin;
  GPIO_InitStruct.Mode = GPIO_MODE_OUTPUT_PP;
  GPIO_InitStruct.Pull = GPIO_NOPULL;
  GPIO_InitStruct.Speed = GPIO_SPEED_FREQ_VERY_HIGH;
  HAL_GPIO_Init(GPIOD, &GPIO_InitStruct);

  /*Configure GPIO pins : DISP_GRID0_Pin DISP_GRID1_Pin DISP_GRID2_Pin DISP_DP_Pin */
  GPIO_InitStruct.Pin = DISP_GRID0_Pin|DISP_GRID1_Pin|DISP_GRID2_Pin|DISP_DP_Pin;
  GPIO_InitStruct.Mode = GPIO_MODE_OUTPUT_PP;
  GPIO_InitStruct.Pull = GPIO_NOPULL;
  GPIO_InitStruct.Speed = GPIO_SPEED_FREQ_LOW;
  HAL_GPIO_Init(GPIOG, &GPIO_InitStruct);

  /*Configure GPIO pins : DISP_A_Pin DISP_F_Pin DISP_B_Pin DISP_G_Pin
                           DISP_C_Pin DISP_D_Pin DISP_E_Pin */
  GPIO_InitStruct.Pin = DISP_A_Pin|DISP_F_Pin|DISP_B_Pin|DISP_G_Pin
                          |DISP_C_Pin|DISP_D_Pin|DISP_E_Pin;
  GPIO_InitStruct.Mode = GPIO_MODE_OUTPUT_PP;
  GPIO_InitStruct.Pull = GPIO_NOPULL;
  GPIO_InitStruct.Speed = GPIO_SPEED_FREQ_VERY_HIGH;
  HAL_GPIO_Init(GPIOG, &GPIO_InitStruct);

}

void Error_Handler(void)
{
  __disable_irq();
  while (1)
  {
  }
}
